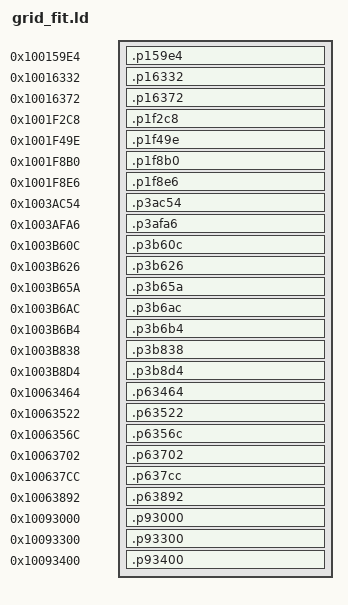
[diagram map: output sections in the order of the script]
SECTIONS {
.p159e4 0x100159e4 : { *(.p159e4) }
.p16332 0x10016332 : { *(.p16332) }
.p16372 0x10016372 : { *(.p16372) }
.p1f2c8 0x1001f2c8 : { *(.p1f2c8) }
.p1f49e 0x1001f49e : { *(.p1f49e) }
.p1f8b0 0x1001f8b0 : { *(.p1f8b0) }
.p1f8e6 0x1001f8e6 : { *(.p1f8e6) }
.p3ac54 0x1003ac54 : { *(.p3ac54) }
.p3afa6 0x1003afa6 : { *(.p3afa6) }
.p3b60c 0x1003b60c : { *(.p3b60c) }
.p3b626 0x1003b626 : { *(.p3b626) }
.p3b65a 0x1003b65a : { *(.p3b65a) }
.p3b6ac 0x1003b6ac : { *(.p3b6ac) }
.p3b6b4 0x1003b6b4 : { *(.p3b6b4) }
.p3b838 0x1003b838 : { *(.p3b838) }
.p3b8d4 0x1003b8d4 : { *(.p3b8d4) }
.p63464 0x10063464 : { *(.p63464) }
.p63522 0x10063522 : { *(.p63522) }
.p6356c 0x1006356c : { *(.p6356c) }
.p63702 0x10063702 : { *(.p63702) }
.p637cc 0x100637cc : { *(.p637cc) }
.p63892 0x10063892 : { *(.p63892) }
.p93000 0x10093000 : { *(.p93000) }
.p93300 0x10093300 : { *(.p93300) }
.p93400 0x10093400 : { *(.p93400) }
}
advance = 0x1008d01d;
pos = 0x10041cd1;
garden_select = 0x1001f43d;
garden_resume = 0x1001f2d3;
garden_sfx = 0x1001f347;
item_built = 0x1003b787;
item_loop = 0x1003b609;
